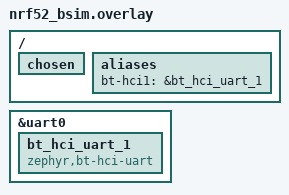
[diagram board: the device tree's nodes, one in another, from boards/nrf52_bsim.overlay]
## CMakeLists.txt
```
# Copyright (C) 2026 Xiaomi Corporation
# SPDX-License-Identifier: Apache-2.0

cmake_minimum_required(VERSION 3.20.0)
find_package(Zephyr REQUIRED HINTS $ENV{ZEPHYR_BASE})
project(observer_multi)

target_sources(app PRIVATE src/main.c)
```

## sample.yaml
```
sample:
  name: Bluetooth Multi-Controller Observer
  description: Demonstrates BLE scanning on two HCI controllers simultaneously
tests:
  sample.bluetooth.observer_multi:
    harness: bluetooth
    build_only: true
    platform_allow:
      - native_sim
      - qemu_x86
    integration_platforms:
      - native_sim
      - qemu_x86
    tags: bluetooth
```

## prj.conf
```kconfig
#
# Copyright (C) 2026 Xiaomi Corporation
#
# SPDX-License-Identifier: Apache-2.0
#

CONFIG_BT=y
CONFIG_BT_OBSERVER=y
CONFIG_BT_HCI_MAX_DEV=2
CONFIG_MAIN_STACK_SIZE=4096
CONFIG_QEMU_EXTRA_FLAGS="-chardev socket,id=bt1,path=/tmp/bt-server-1,server=off -device isa-serial,index=2,irq=5,chardev=bt1"
```

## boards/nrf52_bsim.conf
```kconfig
#
# Copyright (C) 2026 Xiaomi Corporation
#
# SPDX-License-Identifier: Apache-2.0
#

# uart0 is repurposed as the second HCI UART for the bsim multi-controller
# test; disable the UART console so it does not conflict.
CONFIG_UART_CONSOLE=n

CONFIG_LOG=y
CONFIG_ASSERT=y
```

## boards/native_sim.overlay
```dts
/*
 * Copyright (C) 2026 Xiaomi Corporation
 *
 * SPDX-License-Identifier: Apache-2.0
 */

/ {
	aliases {
		bt-hci1 = &bt_hci_userchan_1;
	};

	bt_hci_userchan_1: bt_hci_userchan_1 {
		compatible = "zephyr,bt-hci-userchan";
		status = "okay";
	};
};
```

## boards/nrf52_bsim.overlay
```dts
/*
 * Copyright (C) 2026 Xiaomi Corporation
 *
 * SPDX-License-Identifier: Apache-2.0
 */

/*
 * Board overlay for nrf52_bsim:
 * - Frees uart0 from console use so it can serve as the second HCI UART.
 * - Adds bt_hci_uart_1 as a child of uart0.
 * - Exposes it via the bt-hci1 alias so the observer_multi app can
 *   retrieve it with DEVICE_DT_GET(DT_ALIAS(bt_hci1)).
 */

/ {
	chosen {
		/delete-property/ zephyr,console;
	};

	aliases {
		bt-hci1 = &bt_hci_uart_1;
	};
};

&uart0 {
	bt_hci_uart_1: bt_hci_uart_1 {
		compatible = "zephyr,bt-hci-uart";
		status = "okay";
	};
};
```

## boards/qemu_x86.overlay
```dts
/*
 * Copyright (C) 2026 Xiaomi Corporation
 *
 * SPDX-License-Identifier: Apache-2.0
 */

/ {
	aliases {
		bt-hci1 = &bt_hci_uart_1;
	};

	soc {
		uart2: uart@3e8 {
			compatible = "ns16550";
			reg = <0x000003e8 0x100>;
			io-mapped;
			clock-frequency = <1843200>;
			interrupts = <5 IRQ_TYPE_LOWEST_EDGE_RISING 3>;
			interrupt-parent = <&intc>;
			reg-shift = <0>;
			status = "okay";
			current-speed = <115200>;

			bt_hci_uart_1: bt_hci_uart_1 {
				compatible = "zephyr,bt-hci-uart";
				status = "okay";
			};
		};
	};
};
```

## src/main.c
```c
/*
 * Copyright (C) 2026 Xiaomi Corporation
 *
 * SPDX-License-Identifier: Apache-2.0
 */

/*
 * Multi-controller observer test.
 * Enables two HCI controllers, starts scanning on both simultaneously,
 * then stops scanning.
 */

#include <zephyr/kernel.h>
#include <zephyr/device.h>
#include <zephyr/sys/printk.h>
#include <zephyr/bluetooth/bluetooth.h>

static const struct device *hci1 = DEVICE_DT_GET(DT_ALIAS(bt_hci1));

static void device_found_0(const bt_addr_le_t *addr, int8_t rssi, uint8_t type,
			   struct net_buf_simple *ad)
{
	printk("[hci0] %s RSSI %d type %u len %u\n", bt_addr_le_str(addr), rssi, type, ad->len);
}

static void device_found_1(const bt_addr_le_t *addr, int8_t rssi, uint8_t type,
			   struct net_buf_simple *ad)
{
	printk("[hci1] %s RSSI %d type %u len %u\n", bt_addr_le_str(addr), rssi, type, ad->len);
}

int main(void)
{
	int err;

	printk("Multi-controller observer test\n");

	/* Enable default controller */
	err = bt_enable(NULL);
	if (err) {
		printk("bt_enable failed (err %d)\n", err);
		return 0;
	}
	printk("Default controller initialized\n");

	/* Enable second controller */
	err = bt_dev_enable(hci1, NULL);
	if (err) {
		printk("bt_dev_enable failed (err %d)\n", err);
		return 0;
	}
	printk("Second controller initialized\n");

	/* Start scan on hci0 */
	struct bt_le_scan_param param0 = {
		.type = BT_LE_SCAN_TYPE_PASSIVE,
		.options = BT_LE_SCAN_OPT_FILTER_DUPLICATE,
		.interval = BT_GAP_SCAN_FAST_INTERVAL,
		.window = BT_GAP_SCAN_FAST_WINDOW,
		.hci_dev = NULL, /* default controller */
	};

	err = bt_le_scan_start(&param0, device_found_0);
	if (err) {
		printk("Scan start hci0 failed (err %d)\n", err);
		return 0;
	}
	printk("Scanning on hci0...\n");

	/* Start scan on hci1 */
	struct bt_le_scan_param param1 = {
		.type = BT_LE_SCAN_TYPE_PASSIVE,
		.options = BT_LE_SCAN_OPT_FILTER_DUPLICATE,
		.interval = BT_GAP_SCAN_FAST_INTERVAL,
		.window = BT_GAP_SCAN_FAST_WINDOW,
		.hci_dev = hci1,
	};

	err = bt_le_scan_start(&param1, device_found_1);
	if (err) {
		printk("Scan start hci1 failed (err %d)\n", err);
		/* Continue with hci0 only */
	} else {
		printk("Scanning on hci1...\n");
	}

	/* Let both scan for 8 seconds */
	k_sleep(K_SECONDS(8));

	printk("Stopping all scans...\n");
	bt_le_scan_stop();

	/* Disable second controller */
	bt_dev_disable(hci1);
	printk("Second controller disabled\n");

	printk("Test complete\n");
	return 0;
}
```
